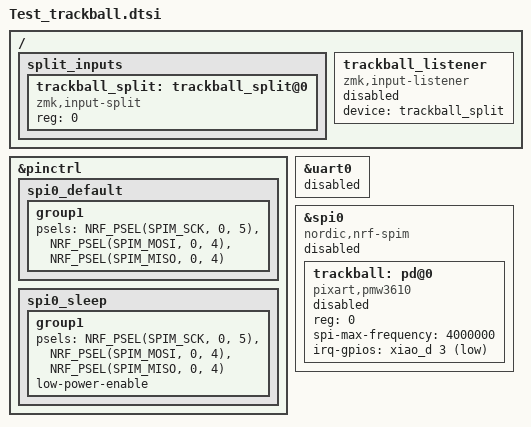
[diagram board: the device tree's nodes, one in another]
&pinctrl {
    spi0_default: spi0_default {
        group1 {
            psels = <NRF_PSEL(SPIM_SCK, 0, 5)>,
                <NRF_PSEL(SPIM_MOSI, 0, 4)>,
                <NRF_PSEL(SPIM_MISO, 0, 4)>;
        };
    };

    spi0_sleep: spi0_sleep {
        group1 {
            psels = <NRF_PSEL(SPIM_SCK, 0, 5)>,
                <NRF_PSEL(SPIM_MOSI, 0, 4)>,
                <NRF_PSEL(SPIM_MISO, 0, 4)>;
            low-power-enable;
        };
    };
};

&uart0 {
	status = "disabled";
};

&spi0 {
    status = "disabled";
    compatible = "nordic,nrf-spim";

    trackball: pd@0 {
        status = "disabled";
        compatible = "pixart,pmw3610";
        reg = <0>;
        spi-max-frequency = <4000000>;
        irq-gpios = <&xiao_d 3 (GPIO_ACTIVE_LOW | GPIO_PULL_UP)>;
    };
};


/*input-split*/
/ {
    split_inputs {
        #address-cells = <1>;
        #size-cells = <0>;

        trackball_split: trackball_split@0 {
            compatible = "zmk,input-split";
            reg = <0>;
        };
    };

    trackball_listener: trackball_listener {
        compatible = "zmk,input-listener";
        status = "disabled";
        device = <&trackball_split>;
    };
};


